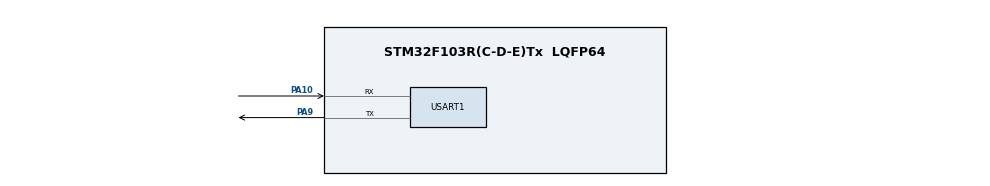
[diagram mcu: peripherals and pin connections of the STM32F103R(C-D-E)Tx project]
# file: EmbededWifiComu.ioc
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FREERTOS.Tasks01=SenderTask,0,128,SenderFunc,Default,NULL,Dynamic,NULL,NULL;RecieverTask,0,128,RecieverFunc,Default,NULL,Dynamic,NULL,NULL
Mcu.Family=STM32F1
Mcu.Name=STM32F103R(C-D-E)Tx
Mcu.Package=LQFP64
NVIC.PriorityGroup=NVIC_PRIORITYGROUP_4
NVIC.TIM3_IRQn=true\:0\:0\:false\:false\:true\:false\:false\:true
NVIC.TimeBase=TIM3_IRQn
NVIC.TimeBaseIP=TIM3
NVIC.USART1_IRQn=true\:5\:0\:false\:false\:true\:true\:true\:true
PA10.Mode=Asynchronous
PA10.Signal=USART1_RX
PA13.Mode=Serial_Wire
PA13.Signal=SYS_JTMS-SWDIO
PA14.Mode=Serial_Wire
PA14.Signal=SYS_JTCK-SWCLK
PA9.Mode=Asynchronous
PA9.Signal=USART1_TX
PD0-OSC_IN.Mode=HSE-External-Oscillator
PD0-OSC_IN.Signal=RCC_OSC_IN
PD1-OSC_OUT.Mode=HSE-External-Oscillator
PD1-OSC_OUT.Signal=RCC_OSC_OUT
ProjectManager.HeapSize=0x200
ProjectManager.StackSize=0x400
ProjectManager.TargetToolchain=STM32CubeIDE
RCC.APB1Freq_Value=8000000
RCC.APB2Freq_Value=8000000
USART1.VirtualMode=VM_ASYNC
VP_FREERTOS_VS_CMSIS_V1.Mode=CMSIS_V1
VP_SYS_VS_tim3.Mode=TIM3
board=custom

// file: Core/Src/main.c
/* USER CODE BEGIN Header */
/**
  ******************************************************************************
  * @file           : main.c
  * @brief          : Main program body
  ******************************************************************************
  * @attention
  *
  * <h2><center>&copy; Copyright (c) 2020 STMicroelectronics.
  * All rights reserved.</center></h2>
  *
  * This software component is licensed by ST under BSD 3-Clause license,
  * the "License"; You may not use this file except in compliance with the
  * License. You may obtain a copy of the License at:
  *                        opensource.org/licenses/BSD-3-Clause
  *
  ******************************************************************************
  */
/* USER CODE END Header */

#include "main.h"
#include "cmsis_os.h"

/* USER CODE BEGIN Includes */
#include "display.h"
#include "wifi_socket.h"
#include <stdio.h>
#include <string.h>
/* USER CODE END Includes */

UART_HandleTypeDef huart1;

osThreadId SenderTaskHandle;
osThreadId RecieverTaskHandle;

void SystemClock_Config(void);
static void MX_GPIO_Init(void);
static void MX_USART1_UART_Init(void);
void SenderFunc(void const * argument);
void RecieverFunc(void const * argument);

/* USER CODE BEGIN 0 */
uint8_t rxBuffer[128];
typedef struct
{
	char msg[128];
} mailMsg;
// Sender Queue
osMailQId mailSenderHandle;
// Receiver Queue
osMailQId mailRecieverHandle;

/* USER CODE END 0 */

int main(void)
{

  /* MCU Configuration--------------------------------------------------------*/

  /* Reset of all peripherals, Initializes the Flash interface and the Systick. */
  HAL_Init();

  /* Configure the system clock */
  SystemClock_Config();

  /* Initialize all configured peripherals */
  MX_GPIO_Init();
  MX_USART1_UART_Init();

  /* USER CODE BEGIN RTOS_QUEUES */
  /* add queues, ... */
  osMailQDef(mailSender, 10, mailMsg);
  mailSenderHandle = osMailCreate(osMailQ(mailSender), NULL);

  osMailQDef(mailRecieverHandle, 10, mailMsg);
  mailRecieverHandle = osMailCreate(osMailQ(mailRecieverHandle), NULL);
  /* USER CODE END RTOS_QUEUES */

  /* Create the thread(s) */
  /* definition and creation of SenderTask */
  osThreadDef(SenderTask, SenderFunc, osPriorityNormal, 0, 128);
  SenderTaskHandle = osThreadCreate(osThread(SenderTask), NULL);

  /* definition and creation of RecieverTask */
  osThreadDef(RecieverTask, RecieverFunc, osPriorityNormal, 0, 128);
  RecieverTaskHandle = osThreadCreate(osThread(RecieverTask), NULL);

  /* Start scheduler */
  osKernelStart();

  /* We should never get here as control is now taken by the scheduler */
  /* Infinite loop */
  while (1)
  {

  }
}

void SystemClock_Config(void)
{
  RCC_OscInitTypeDef RCC_OscInitStruct = {0};
  RCC_ClkInitTypeDef RCC_ClkInitStruct = {0};

  /** Initializes the CPU, AHB and APB busses clocks
  */
  RCC_OscInitStruct.OscillatorType = RCC_OSCILLATORTYPE_HSI;
  RCC_OscInitStruct.HSIState = RCC_HSI_ON;
  RCC_OscInitStruct.HSICalibrationValue = RCC_HSICALIBRATION_DEFAULT;
  RCC_OscInitStruct.PLL.PLLState = RCC_PLL_NONE;
  if (HAL_RCC_OscConfig(&RCC_OscInitStruct) != HAL_OK)
  {
    Error_Handler();
  }
  /** Initializes the CPU, AHB and APB busses clocks
  */
  RCC_ClkInitStruct.ClockType = RCC_CLOCKTYPE_HCLK|RCC_CLOCKTYPE_SYSCLK
                              |RCC_CLOCKTYPE_PCLK1|RCC_CLOCKTYPE_PCLK2;
  RCC_ClkInitStruct.SYSCLKSource = RCC_SYSCLKSOURCE_HSI;
  RCC_ClkInitStruct.AHBCLKDivider = RCC_SYSCLK_DIV1;
  RCC_ClkInitStruct.APB1CLKDivider = RCC_HCLK_DIV1;
  RCC_ClkInitStruct.APB2CLKDivider = RCC_HCLK_DIV1;

  if (HAL_RCC_ClockConfig(&RCC_ClkInitStruct, FLASH_LATENCY_0) != HAL_OK)
  {
    Error_Handler();
  }
}

static void MX_USART1_UART_Init(void)
{

  huart1.Instance = USART1;
  huart1.Init.BaudRate = 115200;
  huart1.Init.WordLength = UART_WORDLENGTH_8B;
  huart1.Init.StopBits = UART_STOPBITS_1;
  huart1.Init.Parity = UART_PARITY_NONE;
  huart1.Init.Mode = UART_MODE_TX_RX;
  huart1.Init.HwFlowCtl = UART_HWCONTROL_NONE;
  huart1.Init.OverSampling = UART_OVERSAMPLING_16;
  if (HAL_UART_Init(&huart1) != HAL_OK)
  {
    Error_Handler();
  }

}

static void MX_GPIO_Init(void)
{

  /* GPIO Ports Clock Enable */
  __HAL_RCC_GPIOD_CLK_ENABLE();
  __HAL_RCC_GPIOA_CLK_ENABLE();

}

/* USER CODE BEGIN 4 */
void HAL_UART_RxCpltCallback(UART_HandleTypeDef *huart)
{
	if(huart->Instance==USART1){
		static uint8_t uRx_Data[128];
		static unsigned int uLength = 0;
		static mailMsg * send_msg;
		static osStatus send_status;
		static char send_error[100];
		if(rxBuffer[0] == '\n')
		{
			uLength -= 1;
			send_msg = (mailMsg *)osMailAlloc(mailSenderHandle, osWaitForever);
			for (int i=0; i<uLength; i++){
				send_msg->msg[i] = uRx_Data[i];
			}
			send_status = osMailPut(mailSenderHandle, send_msg);
			if (send_status == osOK){

			}else{
				sprintf(send_error, "Fail to put into sender queue. The status: %d\r\n", send_status);
				HAL_UART_Transmit(&huart1, (uint8_t*)send_error, strlen(send_error), HAL_MAX_DELAY);
			}
			uLength = 0;
		}else{
			uRx_Data[uLength] = rxBuffer[0];
			uLength++;
			// TODO handle the case if uLength is bigger than the buffer length
		}

	}
}

/* USER CODE END 4 */

void SenderFunc(void const * argument)
{
  /* USER CODE BEGIN 5 */
	osEvent sender_buffer_event;
	mailMsg *p_send_msg;
	char info[200];
  /* Infinite loop */
  for(;;)
  {
	  sender_buffer_event = osMailGet(mailSenderHandle, osWaitForever);
	  if (sender_buffer_event.status == osEventMail)
	  {
		  p_send_msg = sender_buffer_event.value.p;
		  send_msg(p_send_msg->msg);

		  sprintf(info, "Successfully send the: %s \r\n", p_send_msg->msg);
		  HAL_UART_Transmit(&huart1, (uint8_t*)info, strlen(info), HAL_MAX_DELAY);
		  osMailFree(mailSenderHandle, p_send_msg);
		  osDelay(100);
	  }else{
		  sprintf(info, "Exception. status: %d \r\n", sender_buffer_event.status);
		  HAL_UART_Transmit(&huart1, (uint8_t*)info, strlen(info), HAL_MAX_DELAY);
	  }
  }
  /* USER CODE END 5 */
}

void RecieverFunc(void const * argument)
{
  for(;;)
  {
    osDelay(1);
  }
}

 /**
  * @brief  Period elapsed callback in non blocking mode
  * @note   This function is called  when TIM3 interrupt took place, inside
  * HAL_TIM_IRQHandler(). It makes a direct call to HAL_IncTick() to increment
  * a global variable "uwTick" used as application time base.
  * @param  htim : TIM handle
  * @retval None
  */
void HAL_TIM_PeriodElapsedCallback(TIM_HandleTypeDef *htim)
{
  if (htim->Instance == TIM3) {
    HAL_IncTick();
  }
}

void Error_Handler(void)
{
}

/************************ (C) COPYRIGHT STMicroelectronics *****END OF FILE****/
